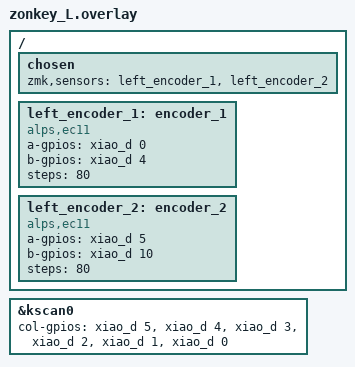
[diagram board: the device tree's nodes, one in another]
#include "zonkey.dtsi"

/ {
    chosen {
        zmk,sensors = <&left_encoder_1 &left_encoder_2>;
    };

    left_encoder_1: encoder_1 {
        compatible = "alps,ec11";
        a-gpios = <&xiao_d 0 (GPIO_ACTIVE_HIGH | GPIO_PULL_UP)>;
        b-gpios = <&xiao_d 4 (GPIO_ACTIVE_HIGH | GPIO_PULL_UP)>; 
        steps = <80>;
        status = "okay";
    };

    left_encoder_2: encoder_2 {
        compatible = "alps,ec11";
        a-gpios = <&xiao_d 5 (GPIO_ACTIVE_HIGH | GPIO_PULL_UP)>;
        b-gpios = <&xiao_d 10 (GPIO_ACTIVE_HIGH | GPIO_PULL_UP)>; 
        steps = <80>;
        status = "okay";
    };
};

&kscan0 {
    col-gpios
        = <&xiao_d 5 GPIO_ACTIVE_HIGH>
        , <&xiao_d 4 GPIO_ACTIVE_HIGH> 
        , <&xiao_d 3 GPIO_ACTIVE_HIGH> 
        , <&xiao_d 2 GPIO_ACTIVE_HIGH> 
        , <&xiao_d 1 GPIO_ACTIVE_HIGH>
        , <&xiao_d 0 GPIO_ACTIVE_HIGH>
        ;
};
